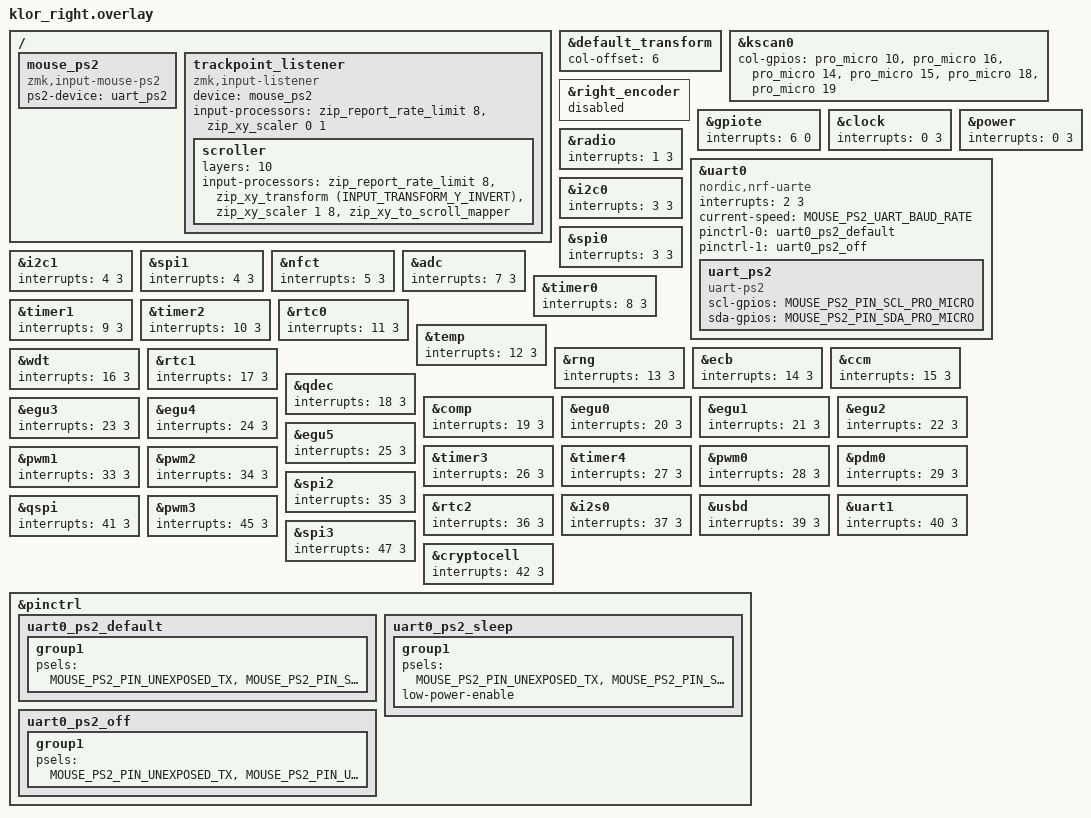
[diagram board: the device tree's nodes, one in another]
/*
 * Copyright (c) 2022 GEIST
 *
 * SPDX-License-Identifier: MIT
 */

#include "klor.dtsi"
#include <dt-bindings/zmk/pointing.h>
#include <input/processors.dtsi>
#include <dt-bindings/zmk/input_transform.h>
#include <zephyr/dt-bindings/input/input-event-codes.h>

&default_transform {
    col-offset = <6>;
};

&kscan0 {
    col-gpios
        = <&pro_micro 10 GPIO_ACTIVE_HIGH>
        , <&pro_micro 16 GPIO_ACTIVE_HIGH>
        , <&pro_micro 14 GPIO_ACTIVE_HIGH>
        , <&pro_micro 15 GPIO_ACTIVE_HIGH>
        , <&pro_micro 18 GPIO_ACTIVE_HIGH>
        , <&pro_micro 19 GPIO_ACTIVE_HIGH>
        ;
};

&right_encoder {
    status = "disabled";
};

/* --- TRACKPOINT HARDWARE CONFIG --- */

// Safely relocated to TXO and RXI pins to avoid matrix conflicts!
#define MOUSE_PS2_PIN_SCL_PRO_MICRO <&pro_micro 0 GPIO_ACTIVE_HIGH>
#define MOUSE_PS2_PIN_SDA_PRO_MICRO <&pro_micro 1 GPIO_ACTIVE_HIGH>

// Pinctrl definition for the new DATA pin (pro_micro 1 is P0.08)
#define MOUSE_PS2_PIN_SDA_PINCTRL <NRF_PSEL(UART_RX, 0, 8)>

// Unexposed pins used to "fake" the UART out during transmit mode
#define MOUSE_PS2_PIN_UNEXPOSED_TX <NRF_PSEL(UART_TX, 0, 27)>
#define MOUSE_PS2_PIN_UNEXPOSED_RX <NRF_PSEL(UART_RX, 0, 28)>

#define MOUSE_PS2_UART_BAUD_RATE <14400>

/* 1. INTERRUPT HACKING */
&gpiote { interrupts = < 6 0 >; };
&clock { interrupts = < 0 3 >; };
&power { interrupts = < 0 3 >; };
&radio { interrupts = < 1 3 >; };
&uart0 { interrupts = < 2 3 >; };
&i2c0 { interrupts = < 3 3 >; };
&spi0 { interrupts = < 3 3 >; };
&i2c1 { interrupts = < 4 3 >; };
&spi1 { interrupts = < 4 3 >; };
&nfct { interrupts = < 5 3 >; };
&adc { interrupts = < 7 3 >; };
&timer0 { interrupts = < 8 3 >; };
&timer1 { interrupts = < 9 3 >; };
&timer2 { interrupts = < 10 3 >; };
&rtc0 { interrupts = < 11 3 >; };
&temp { interrupts = < 12 3 >; };
&rng { interrupts = < 13 3 >; };
&ecb { interrupts = < 14 3 >; };
&ccm { interrupts = < 15 3 >; };
&wdt { interrupts = < 16 3 >; };
&rtc1 { interrupts = < 17 3 >; };
&qdec { interrupts = < 18 3 >; };
&comp { interrupts = < 19 3 >; };
&egu0 { interrupts = < 20 3 >; };
&egu1 { interrupts = < 21 3 >; };
&egu2 { interrupts = < 22 3 >; };
&egu3 { interrupts = < 23 3 >; };
&egu4 { interrupts = < 24 3 >; };
&egu5 { interrupts = < 25 3 >; };
&timer3 { interrupts = < 26 3 >; };
&timer4 { interrupts = < 27 3 >; };
&pwm0 { interrupts = < 28 3 >; };
&pdm0 { interrupts = < 29 3 >; };
&pwm1 { interrupts = < 33 3 >; };
&pwm2 { interrupts = < 34 3 >; };
&spi2 { interrupts = < 35 3 >; };
&rtc2 { interrupts = < 36 3 >; };
&i2s0 { interrupts = < 37 3 >; };
&usbd { interrupts = < 39 3 >; };
&uart1 { interrupts = < 40 3 >; };
&qspi { interrupts = < 41 3 >; };
&pwm3 { interrupts = < 45 3 >; };
&spi3 { interrupts = < 47 3 >; };
&cryptocell { interrupts = < 42 3 >; };

/* 2. PIN CONTROL STATES */
&pinctrl {
    uart0_ps2_default: uart0_ps2_default {
        group1 { psels = MOUSE_PS2_PIN_UNEXPOSED_TX, MOUSE_PS2_PIN_SDA_PINCTRL; };
    };
    uart0_ps2_sleep: uart0_ps2_sleep {
        group1 { psels = MOUSE_PS2_PIN_UNEXPOSED_TX, MOUSE_PS2_PIN_SDA_PINCTRL; low-power-enable; };
    };
    uart0_ps2_off: uart0_ps2_off {
        group1 { psels = MOUSE_PS2_PIN_UNEXPOSED_TX, MOUSE_PS2_PIN_UNEXPOSED_RX; };
    };
};

/* 3. HARDWARE UART OVERRIDE */
&uart0 {
    status = "okay"; /* WAKES UP THE HARDWARE ON NICE!NANO */
    compatible = "nordic,nrf-uarte";
    current-speed = MOUSE_PS2_UART_BAUD_RATE;
    pinctrl-0 = <&uart0_ps2_default>;
    pinctrl-1 = <&uart0_ps2_off>;
    pinctrl-names = "default", "sleep";

    uart_ps2: uart_ps2 {
        compatible = "uart-ps2";
        scl-gpios = MOUSE_PS2_PIN_SCL_PRO_MICRO;
        sda-gpios = MOUSE_PS2_PIN_SDA_PRO_MICRO;
    };
};

/* 4. MOUSE DRIVER INSTANCE */
/ {
    mouse_ps2: mouse_ps2 {
        compatible = "zmk,input-mouse-ps2";
        ps2-device = <&uart_ps2>;
    };
};

/* 5. ZMK INPUT LISTENER & PROCESSORS */
/{
    trackpoint_listener: trackpoint_listener {
        compatible = "zmk,input-listener";
        device = <&mouse_ps2>;

        input-processors = 
            <&zip_report_rate_limit 8>, /* Caps reporting to ~125Hz to save BLE */
            <&zip_xy_scaler 0 1>;

        scroller {
            layers = <10>;
            input-processors = 
                <&zip_report_rate_limit 8>,
                <&zip_xy_transform (INPUT_TRANSFORM_Y_INVERT)>,
                <&zip_xy_scaler 1 8>,
                <&zip_xy_to_scroll_mapper>;
        };
    };
};
